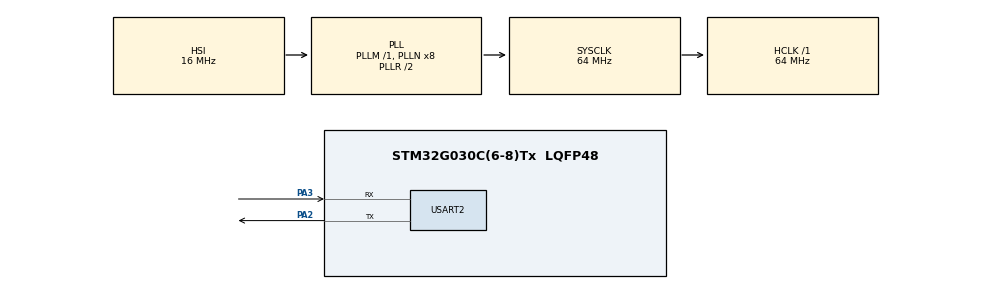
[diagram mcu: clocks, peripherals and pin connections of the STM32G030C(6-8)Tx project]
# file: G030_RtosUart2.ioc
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FREERTOS.Tasks01=defaultTask,24,128,StartDefaultTask,Default,NULL,Dynamic,NULL,NULL
FREERTOS.configTIMER_TASK_STACK_DEPTH=128
FREERTOS.configTOTAL_HEAP_SIZE=1024
FREERTOS.configUSE_NEWLIB_REENTRANT=1
Mcu.Family=STM32G0
Mcu.Name=STM32G030C(6-8)Tx
Mcu.Package=LQFP48
NVIC.TIM14_IRQn=true\:3\:0\:false\:false\:true\:false\:false\:true
NVIC.TimeBase=TIM14_IRQn
NVIC.TimeBaseIP=TIM14
NVIC.USART2_IRQn=true\:3\:0\:false\:false\:true\:true\:true\:true
PA2.Mode=Asynchronous
PA2.Signal=USART2_TX
PA3.Mode=Asynchronous
PA3.Signal=USART2_RX
PC14-OSC32_IN\ (PC14).Mode=LSE-External-Oscillator
PC14-OSC32_IN\ (PC14).Signal=RCC_OSC32_IN
PC15-OSC32_OUT\ (PC15).Mode=LSE-External-Oscillator
PC15-OSC32_OUT\ (PC15).Signal=RCC_OSC32_OUT
ProjectManager.HeapSize=0x200
ProjectManager.StackSize=0x400
ProjectManager.TargetToolchain=STM32CubeIDE
RCC.ADCFreq_Value=64000000
RCC.AHBFreq_Value=64000000
RCC.CortexFreq_Value=64000000
RCC.EXTERNAL_CLOCK_VALUE=12288000
RCC.HCLKFreq_Value=64000000
RCC.HSE_VALUE=8000000
RCC.HSI_VALUE=16000000
RCC.RTCClockSelection=RCC_RTCCLKSOURCE_LSE
RCC.SYSCLKFreq_VALUE=64000000
RCC.SYSCLKSource=RCC_SYSCLKSOURCE_PLLCLK
RCC.VCOOutputFreq_Value=128000000
USART2.VirtualMode-Asynchronous=VM_ASYNC
VP_FREERTOS_VS_CMSIS_V2.Mode=CMSIS_V2
VP_SYS_VS_tim14.Mode=TIM14
board=custom

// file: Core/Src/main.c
/* USER CODE BEGIN Header */
/**
 ******************************************************************************
 * @file           : main.c
 * @brief          : Main program body
 ******************************************************************************
 * @attention
 *
 * <h2><center>&copy; Copyright (c) 2021 STMicroelectronics.
 * All rights reserved.</center></h2>
 *
 * This software component is licensed by ST under BSD 3-Clause license,
 * the "License"; You may not use this file except in compliance with the
 * License. You may obtain a copy of the License at:
 *                        opensource.org/licenses/BSD-3-Clause
 *
 ******************************************************************************
 */
/* USER CODE END Header */
#include "main.h"
#include "cmsis_os.h"
#include "usart.h"
#include "gpio.h"

/* USER CODE BEGIN Includes */
#include "string.h"
#include "stdio.h"
#include "uart_debug.h"
#include "shell_port.h"

/* USER CODE END Includes */

/* USER CODE BEGIN PV */
uint8_t uartRxData[1] = {0 };

/* USER CODE END PV */

void SystemClock_Config(void);
void MX_FREERTOS_Init(void);
/* USER CODE BEGIN PFP */
/************************************函数注册方法示例***********************************/
int test(int i, char ch, char *str)
{
    printf("input int: %d, char: %c, string: %s\r\n", i, ch, str);

    return 0;
}
//导出到命令列表里
SHELL_EXPORT_CMD(SHELL_CMD_PERMISSION(0)|SHELL_CMD_TYPE(SHELL_TYPE_CMD_FUNC),
        test, test, test);

int func(int argc, char *agrv[])
{
    printf("%d parameter(s)\r\n", argc);
    for (int i = 1; i < argc; i++)
    {
        printf("%s\r\n", agrv[i]);
    }

    return 0;
}
SHELL_EXPORT_CMD(SHELL_CMD_PERMISSION(0)|SHELL_CMD_TYPE(SHELL_TYPE_CMD_MAIN),
        func, func, test);

/* USER CODE END PFP */

int main(void)
{

    /* MCU Configuration--------------------------------------------------------*/

    /* Reset of all peripherals, Initializes the Flash interface and the Systick. */
    HAL_Init();

    /* Configure the system clock */
    SystemClock_Config();

    /* Initialize all configured peripherals */
    MX_GPIO_Init();
    MX_USART2_UART_Init();
    /* USER CODE BEGIN 2 */
//  HAL_UART_Receive_IT(&huart2, uartRxData, sizeof(uartRxData));
    User_Shell_Init();

    /* USER CODE END 2 */

    /* Init scheduler */
    osKernelInitialize(); /* Call init function for freertos objects (in freertos.c) */
    MX_FREERTOS_Init();
    /* Start scheduler */
    osKernelStart();

    /* We should never get here as control is now taken by the scheduler */
    /* Infinite loop */
    while (1)
    {

    }
}

void SystemClock_Config(void)
{
    RCC_OscInitTypeDef RCC_OscInitStruct = {0 };
    RCC_ClkInitTypeDef RCC_ClkInitStruct = {0 };

    /** Configure the main internal regulator output voltage
     */
    HAL_PWREx_ControlVoltageScaling(PWR_REGULATOR_VOLTAGE_SCALE1);
    /** Initializes the RCC Oscillators according to the specified parameters
     * in the RCC_OscInitTypeDef structure.
     */
    RCC_OscInitStruct.OscillatorType = RCC_OSCILLATORTYPE_HSI;
    RCC_OscInitStruct.HSIState = RCC_HSI_ON;
    RCC_OscInitStruct.HSIDiv = RCC_HSI_DIV1;
    RCC_OscInitStruct.HSICalibrationValue = RCC_HSICALIBRATION_DEFAULT;
    RCC_OscInitStruct.PLL.PLLState = RCC_PLL_ON;
    RCC_OscInitStruct.PLL.PLLSource = RCC_PLLSOURCE_HSI;
    RCC_OscInitStruct.PLL.PLLM = RCC_PLLM_DIV1;
    RCC_OscInitStruct.PLL.PLLN = 8;
    RCC_OscInitStruct.PLL.PLLP = RCC_PLLP_DIV2;
    RCC_OscInitStruct.PLL.PLLR = RCC_PLLR_DIV2;
    if (HAL_RCC_OscConfig(&RCC_OscInitStruct) != HAL_OK)
    {
        Error_Handler();
    }
    /** Initializes the CPU, AHB and APB buses clocks
     */
    RCC_ClkInitStruct.ClockType = RCC_CLOCKTYPE_HCLK | RCC_CLOCKTYPE_SYSCLK
            | RCC_CLOCKTYPE_PCLK1;
    RCC_ClkInitStruct.SYSCLKSource = RCC_SYSCLKSOURCE_PLLCLK;
    RCC_ClkInitStruct.AHBCLKDivider = RCC_SYSCLK_DIV1;
    RCC_ClkInitStruct.APB1CLKDivider = RCC_HCLK_DIV1;

    if (HAL_RCC_ClockConfig(&RCC_ClkInitStruct, FLASH_LATENCY_2) != HAL_OK)
    {
        Error_Handler();
    }
}

void HAL_TIM_PeriodElapsedCallback(TIM_HandleTypeDef *htim)
{
    if (htim->Instance == TIM14)
    {
        HAL_IncTick();
    }
}

void Error_Handler(void)
{
    __disable_irq();
    while (1)
    {
    }
}

/************************ (C) COPYRIGHT STMicroelectronics *****END OF FILE****/

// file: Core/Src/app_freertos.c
/* USER CODE BEGIN Header */
/**
  ******************************************************************************
  * File Name          : app_freertos.c
  * Description        : Code for freertos applications
  ******************************************************************************
  * @attention
  *
  * <h2><center>&copy; Copyright (c) 2021 STMicroelectronics.
  * All rights reserved.</center></h2>
  *
  * This software component is licensed by ST under Ultimate Liberty license
  * SLA0044, the "License"; You may not use this file except in compliance with
  * the License. You may obtain a copy of the License at:
  *                             www.st.com/SLA0044
  *
  ******************************************************************************
  */
/* USER CODE END Header */

#include "FreeRTOS.h"
#include "task.h"
#include "main.h"
#include "cmsis_os.h"

/* USER CODE BEGIN Includes */
#include "shell_port.h"
#include "shell.h"

/* USER CODE END Includes */

/* USER CODE BEGIN Variables */
/* Definitions for shellTask */
osThreadId_t shellTaskHandle;
const osThreadAttr_t shellTask_attributes = {
  .name = "shellTask",
  .priority = (osPriority_t) osPriorityNormal1,
  .stack_size = 128 * 4
};

/* USER CODE END Variables */
/* Definitions for defaultTask */
osThreadId_t defaultTaskHandle;
const osThreadAttr_t defaultTask_attributes = {
  .name = "defaultTask",
  .priority = (osPriority_t) osPriorityNormal,
  .stack_size = 128 * 4
};

void StartDefaultTask(void *argument);

void MX_FREERTOS_Init(void); /* (MISRA C 2004 rule 8.1) */

void MX_FREERTOS_Init(void) {

  /* Create the thread(s) */
  /* creation of defaultTask */
  defaultTaskHandle = osThreadNew(StartDefaultTask, NULL, &defaultTask_attributes);

  /* USER CODE BEGIN RTOS_THREADS */
  /* add threads, ... */
  /* creation of shellTask */
  shellTaskHandle = osThreadNew(shellTask, &shell, &shellTask_attributes);

  /* USER CODE END RTOS_THREADS */

}

void StartDefaultTask(void *argument)
{
  for(;;)
  {
    osDelay(1);
  }
}

/************************ (C) COPYRIGHT STMicroelectronics *****END OF FILE****/
